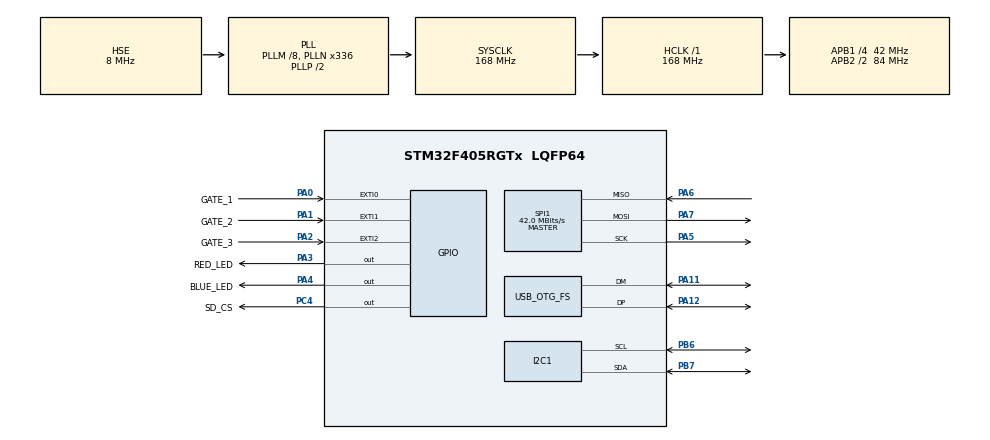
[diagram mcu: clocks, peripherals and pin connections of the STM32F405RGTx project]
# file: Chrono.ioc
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FATFS._MAX_SS=4096
FATFS._USE_LFN=1
Mcu.Family=STM32F4
Mcu.Name=STM32F405RGTx
Mcu.Package=LQFP64
NVIC.EXTI0_IRQn=true\:3\:0\:true\:false\:true\:true\:true
NVIC.EXTI1_IRQn=true\:2\:0\:true\:false\:true\:true\:true
NVIC.EXTI2_IRQn=true\:1\:0\:true\:false\:true\:true\:true
NVIC.OTG_FS_IRQn=true\:0\:0\:false\:false\:true\:false\:true
NVIC.PriorityGroup=NVIC_PRIORITYGROUP_4
PA0-WKUP.GPIO_Label=GATE_1
PA0-WKUP.GPIO_PuPd=GPIO_PULLDOWN
PA0-WKUP.Signal=GPXTI0
PA1.GPIO_Label=GATE_2
PA1.GPIO_PuPd=GPIO_PULLDOWN
PA1.Signal=GPXTI1
PA11.Mode=Device_Only
PA11.Signal=USB_OTG_FS_DM
PA12.Mode=Device_Only
PA12.Signal=USB_OTG_FS_DP
PA2.GPIO_Label=GATE_3
PA2.GPIO_PuPd=GPIO_PULLDOWN
PA2.Signal=GPXTI2
PA3.GPIO_Label=RED_LED
PA3.PinState=GPIO_PIN_SET
PA3.Signal=GPIO_Output
PA4.GPIO_Label=BLUE_LED
PA4.PinState=GPIO_PIN_SET
PA4.Signal=GPIO_Output
PA5.Mode=Full_Duplex_Master
PA5.Signal=SPI1_SCK
PA6.Mode=Full_Duplex_Master
PA6.Signal=SPI1_MISO
PA7.Mode=Full_Duplex_Master
PA7.Signal=SPI1_MOSI
PB6.Mode=I2C
PB6.Signal=I2C1_SCL
PB7.Mode=I2C
PB7.Signal=I2C1_SDA
PC4.GPIO_Label=SD_CS
PC4.Signal=GPIO_Output
PH0-OSC_IN.Mode=HSE-External-Oscillator
PH0-OSC_IN.Signal=RCC_OSC_IN
PH1-OSC_OUT.Mode=HSE-External-Oscillator
PH1-OSC_OUT.Signal=RCC_OSC_OUT
ProjectManager.HeapSize=0x200
ProjectManager.StackSize=0x400
ProjectManager.TargetToolchain=STM32CubeIDE
RCC.48MHZClocksFreq_Value=48000000
RCC.AHBFreq_Value=168000000
RCC.APB1CLKDivider=RCC_HCLK_DIV4
RCC.APB1Freq_Value=42000000
RCC.APB1TimFreq_Value=84000000
RCC.APB2CLKDivider=RCC_HCLK_DIV2
RCC.APB2Freq_Value=84000000
RCC.APB2TimFreq_Value=168000000
RCC.CortexFreq_Value=168000000
RCC.HCLKFreq_Value=168000000
RCC.HSE_VALUE=8000000
RCC.HSI_VALUE=16000000
RCC.LSE_VALUE=32768
RCC.PLLM=8
RCC.PLLN=336
RCC.PLLQ=7
RCC.SYSCLKFreq_VALUE=168000000
RCC.SYSCLKSource=RCC_SYSCLKSOURCE_PLLCLK
RCC.VCOOutputFreq_Value=336000000
SPI1.CalculateBaudRate=42.0 MBits/s
SPI1.Direction=SPI_DIRECTION_2LINES
SPI1.Mode=SPI_MODE_MASTER
SPI1.VirtualType=VM_MASTER
TIM2.Period=0xFFFFFFFF
TIM2.Prescaler=0
USB_DEVICE.CLASS_NAME_FS=CDC
USB_DEVICE.VirtualMode-CDC_FS=Cdc
USB_DEVICE.VirtualModeFS=Cdc_FS
USB_OTG_FS.VirtualMode=Device_Only
VP_FATFS_VS_Generic.Mode=User_defined
VP_TIM2_VS_ClockSourceINT.Mode=Internal
VP_USB_DEVICE_VS_USB_DEVICE_CDC_FS.Mode=CDC_FS
board=custom

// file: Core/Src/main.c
/* USER CODE BEGIN Header */
/**
  ******************************************************************************
  * @file           : main.c
  * @brief          : Main program body
  ******************************************************************************
  * @attention
  *
  * <h2><center>&copy; Copyright (c) 2020 STMicroelectronics.
  * All rights reserved.</center></h2>
  *
  * This software component is licensed by ST under BSD 3-Clause license,
  * the "License"; You may not use this file except in compliance with the
  * License. You may obtain a copy of the License at:
  *                        opensource.org/licenses/BSD-3-Clause
  *
  ******************************************************************************
  */
/* USER CODE END Header */

#include "main.h"
#include "fatfs.h"
#include "usb_device.h"

/* USER CODE BEGIN Includes */
#include "chrono.h"
#include "i2c_display.h"
/* USER CODE END Includes */

I2C_HandleTypeDef hi2c1;

SPI_HandleTypeDef hspi1;

TIM_HandleTypeDef htim2;

/* USER CODE BEGIN PV */
volatile chronograph chrono;
/* USER CODE END PV */

void SystemClock_Config(void);
static void MX_GPIO_Init(void);
static void MX_I2C1_Init(void);
static void MX_SPI1_Init(void);
static void MX_TIM2_Init(void);

int main(void)
{

  /* MCU Configuration--------------------------------------------------------*/

  /* Reset of all peripherals, Initializes the Flash interface and the Systick. */
  HAL_Init();

  /* USER CODE BEGIN Init */
  init_chrono(&chrono);

  /* USER CODE END Init */

  /* Configure the system clock */
  SystemClock_Config();

  /* Initialize all configured peripherals */
  MX_GPIO_Init();
  MX_I2C1_Init();
  MX_USB_DEVICE_Init();
  MX_FATFS_Init();
  MX_SPI1_Init();
  MX_TIM2_Init();
  /* USER CODE BEGIN 2 */

    lcd_init();
    //LCD_Example();

  /* USER CODE END 2 */

  /* Infinite loop */
    while (1)
    {

    }
}

void SystemClock_Config(void)
{
  RCC_OscInitTypeDef RCC_OscInitStruct = {0};
  RCC_ClkInitTypeDef RCC_ClkInitStruct = {0};

  /** Configure the main internal regulator output voltage
  */
  __HAL_RCC_PWR_CLK_ENABLE();
  __HAL_PWR_VOLTAGESCALING_CONFIG(PWR_REGULATOR_VOLTAGE_SCALE1);
  /** Initializes the CPU, AHB and APB busses clocks
  */
  RCC_OscInitStruct.OscillatorType = RCC_OSCILLATORTYPE_HSE;
  RCC_OscInitStruct.HSEState = RCC_HSE_ON;
  RCC_OscInitStruct.PLL.PLLState = RCC_PLL_ON;
  RCC_OscInitStruct.PLL.PLLSource = RCC_PLLSOURCE_HSE;
  RCC_OscInitStruct.PLL.PLLM = 8;
  RCC_OscInitStruct.PLL.PLLN = 336;
  RCC_OscInitStruct.PLL.PLLP = RCC_PLLP_DIV2;
  RCC_OscInitStruct.PLL.PLLQ = 7;
  if (HAL_RCC_OscConfig(&RCC_OscInitStruct) != HAL_OK)
  {
    Error_Handler();
  }
  /** Initializes the CPU, AHB and APB busses clocks
  */
  RCC_ClkInitStruct.ClockType = RCC_CLOCKTYPE_HCLK|RCC_CLOCKTYPE_SYSCLK
                              |RCC_CLOCKTYPE_PCLK1|RCC_CLOCKTYPE_PCLK2;
  RCC_ClkInitStruct.SYSCLKSource = RCC_SYSCLKSOURCE_PLLCLK;
  RCC_ClkInitStruct.AHBCLKDivider = RCC_SYSCLK_DIV1;
  RCC_ClkInitStruct.APB1CLKDivider = RCC_HCLK_DIV4;
  RCC_ClkInitStruct.APB2CLKDivider = RCC_HCLK_DIV2;

  if (HAL_RCC_ClockConfig(&RCC_ClkInitStruct, FLASH_LATENCY_5) != HAL_OK)
  {
    Error_Handler();
  }
}

static void MX_I2C1_Init(void)
{

  hi2c1.Instance = I2C1;
  hi2c1.Init.ClockSpeed = 100000;
  hi2c1.Init.DutyCycle = I2C_DUTYCYCLE_2;
  hi2c1.Init.OwnAddress1 = 0;
  hi2c1.Init.AddressingMode = I2C_ADDRESSINGMODE_7BIT;
  hi2c1.Init.DualAddressMode = I2C_DUALADDRESS_DISABLE;
  hi2c1.Init.OwnAddress2 = 0;
  hi2c1.Init.GeneralCallMode = I2C_GENERALCALL_DISABLE;
  hi2c1.Init.NoStretchMode = I2C_NOSTRETCH_DISABLE;
  if (HAL_I2C_Init(&hi2c1) != HAL_OK)
  {
    Error_Handler();
  }

}

static void MX_SPI1_Init(void)
{

  /* SPI1 parameter configuration*/
  hspi1.Instance = SPI1;
  hspi1.Init.Mode = SPI_MODE_MASTER;
  hspi1.Init.Direction = SPI_DIRECTION_2LINES;
  hspi1.Init.DataSize = SPI_DATASIZE_8BIT;
  hspi1.Init.CLKPolarity = SPI_POLARITY_LOW;
  hspi1.Init.CLKPhase = SPI_PHASE_1EDGE;
  hspi1.Init.NSS = SPI_NSS_SOFT;
  hspi1.Init.BaudRatePrescaler = SPI_BAUDRATEPRESCALER_2;
  hspi1.Init.FirstBit = SPI_FIRSTBIT_MSB;
  hspi1.Init.TIMode = SPI_TIMODE_DISABLE;
  hspi1.Init.CRCCalculation = SPI_CRCCALCULATION_DISABLE;
  hspi1.Init.CRCPolynomial = 10;
  if (HAL_SPI_Init(&hspi1) != HAL_OK)
  {
    Error_Handler();
  }

}

static void MX_TIM2_Init(void)
{

  TIM_ClockConfigTypeDef sClockSourceConfig = {0};
  TIM_MasterConfigTypeDef sMasterConfig = {0};

  htim2.Instance = TIM2;
  htim2.Init.Prescaler = 0;
  htim2.Init.CounterMode = TIM_COUNTERMODE_UP;
  htim2.Init.Period = 0xFFFFFFFF;
  htim2.Init.ClockDivision = TIM_CLOCKDIVISION_DIV1;
  htim2.Init.AutoReloadPreload = TIM_AUTORELOAD_PRELOAD_DISABLE;
  if (HAL_TIM_Base_Init(&htim2) != HAL_OK)
  {
    Error_Handler();
  }
  sClockSourceConfig.ClockSource = TIM_CLOCKSOURCE_INTERNAL;
  if (HAL_TIM_ConfigClockSource(&htim2, &sClockSourceConfig) != HAL_OK)
  {
    Error_Handler();
  }
  sMasterConfig.MasterOutputTrigger = TIM_TRGO_RESET;
  sMasterConfig.MasterSlaveMode = TIM_MASTERSLAVEMODE_DISABLE;
  if (HAL_TIMEx_MasterConfigSynchronization(&htim2, &sMasterConfig) != HAL_OK)
  {
    Error_Handler();
  }
  /* USER CODE BEGIN TIM2_Init 2 */
	HAL_TIM_Base_Start(&htim2);
  /* USER CODE END TIM2_Init 2 */

}

static void MX_GPIO_Init(void)
{
  GPIO_InitTypeDef GPIO_InitStruct = {0};

  /* GPIO Ports Clock Enable */
  __HAL_RCC_GPIOH_CLK_ENABLE();
  __HAL_RCC_GPIOA_CLK_ENABLE();
  __HAL_RCC_GPIOC_CLK_ENABLE();
  __HAL_RCC_GPIOB_CLK_ENABLE();

  /*Configure GPIO pin Output Level */
  HAL_GPIO_WritePin(GPIOA, RED_LED_Pin|BLUE_LED_Pin, GPIO_PIN_SET);

  /*Configure GPIO pin Output Level */
  HAL_GPIO_WritePin(SD_CS_GPIO_Port, SD_CS_Pin, GPIO_PIN_RESET);

  /*Configure GPIO pins : GATE_1_Pin GATE_2_Pin GATE_3_Pin */
  GPIO_InitStruct.Pin = GATE_1_Pin|GATE_2_Pin|GATE_3_Pin;
  GPIO_InitStruct.Mode = GPIO_MODE_IT_RISING;
  GPIO_InitStruct.Pull = GPIO_PULLDOWN;
  HAL_GPIO_Init(GPIOA, &GPIO_InitStruct);

  /*Configure GPIO pins : RED_LED_Pin BLUE_LED_Pin */
  GPIO_InitStruct.Pin = RED_LED_Pin|BLUE_LED_Pin;
  GPIO_InitStruct.Mode = GPIO_MODE_OUTPUT_PP;
  GPIO_InitStruct.Pull = GPIO_NOPULL;
  GPIO_InitStruct.Speed = GPIO_SPEED_FREQ_LOW;
  HAL_GPIO_Init(GPIOA, &GPIO_InitStruct);

  /*Configure GPIO pin : SD_CS_Pin */
  GPIO_InitStruct.Pin = SD_CS_Pin;
  GPIO_InitStruct.Mode = GPIO_MODE_OUTPUT_PP;
  GPIO_InitStruct.Pull = GPIO_NOPULL;
  GPIO_InitStruct.Speed = GPIO_SPEED_FREQ_LOW;
  HAL_GPIO_Init(SD_CS_GPIO_Port, &GPIO_InitStruct);

  /* EXTI interrupt init*/
  HAL_NVIC_SetPriority(EXTI0_IRQn, 3, 0);
  HAL_NVIC_EnableIRQ(EXTI0_IRQn);

  HAL_NVIC_SetPriority(EXTI1_IRQn, 2, 0);
  HAL_NVIC_EnableIRQ(EXTI1_IRQn);

  HAL_NVIC_SetPriority(EXTI2_IRQn, 1, 0);
  HAL_NVIC_EnableIRQ(EXTI2_IRQn);

}

void Error_Handler(void)
{
  /* USER CODE BEGIN Error_Handler_Debug */
  /* User can add his own implementation to report the HAL error return state */
	lcd_put_cur(0,0);
	lcd_send_string("ERROR HANDLER");
  /* USER CODE END Error_Handler_Debug */
}

/************************ (C) COPYRIGHT STMicroelectronics *****END OF FILE****/
